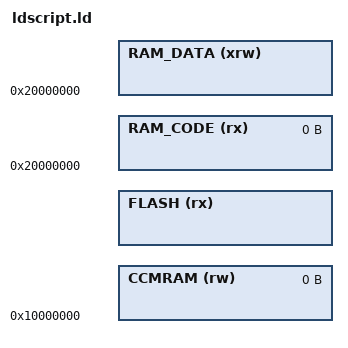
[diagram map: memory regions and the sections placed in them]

/* Specify the memory areas */
MEMORY
{
  RAM_CODE (rx)  : ORIGIN = 0x20000000, LENGTH = 0K
  RAM_DATA (xrw) : ORIGIN = 0x20000000 + LENGTH(RAM_CODE), LENGTH = LD_MAX_DATA_SIZE - LENGTH(RAM_CODE)
  CCMRAM   (rw)  : ORIGIN = 0x10000000, LENGTH = 0K
  FLASH    (rx)  : ORIGIN = 0x8000000 + FLASH_APP_OFFSET, LENGTH = LD_MAX_SIZE - FLASH_APP_OFFSET
}

INCLUDE "variants/ldscript_gen.ld"
